# R7FS3A17 register map
Vendor: Renesas; Series: S3; File version: 1.2
CPU: CM4 r0p1, little endian, MPU, FPU, VTOR, 4 interrupt priority bits
Registers are 8-bit, read-write, reset 0x0 unless marked. A register's access mark holds for its fields unless they carry their own. Offsets are from the block's base; [hi:lo] are bit positions.

## DMA — DMAC Module Activation
Base 0x40005200
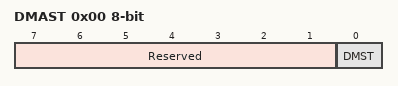
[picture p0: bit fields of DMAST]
0x00 DMAST — DMAC Module Activation Register
  [7:1] Reserved — These bits are read as 0000000. The write value should be 0000000.
  [0] DMST — DMAC Operation Enable
    0=Disabled; 1=Enabled

## DTC — Data Transfer Controller
Base 0x40005400
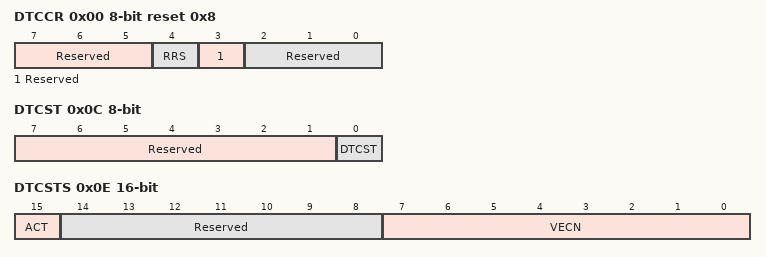
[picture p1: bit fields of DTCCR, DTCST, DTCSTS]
0x00 DTCCR reset 0x8 — DTC Control Register
  [7:5] Reserved — These bits are read as 000. The write value should be 000.
  [4] RRS — DTC Transfer Information Read Skip Enable.
    0=Do not skip transfer information read; 1=Skip transfer information read when vector numbers match
  [3] Reserved — This bit is read as 1. The write value should be 1.
  [2:0] Reserved — These bits are read as 000. The write value should be 000.
0x04 DTCVBR 32-bit — DTC Vector Base Register
  [31:0] DTCVBR — DTC Vector Base Address. Note: A value cannot be set in the lower-order 10 bits. These bits are fixed to 0.
0x0C DTCST — DTC Module Start Register
  [7:1] Reserved — These bits are read as 0000000. The write value should be 0000000.
  [0] DTCST — DTC Module Start
    0=DTC module stop; 1=DTC module start
0x0E DTCSTS 16-bit ro — DTC Status Register
  [15] ACT — DTC Active Flag
    0=DTC transfer operation is not in progress; 1=DTC transfer operation is in progress
  [14:8] Reserved — These bits are read as 0000000.
  [7:0] VECN — DTC-Activating Vector Number Monitoring These bits indicate the vector number for the activating source when DTC transfer is in progress. The value is only valid if DTC transfer is in progress (the value of the ACT flag is 1)

## DBG — Debug Function
Base 0x4001B000
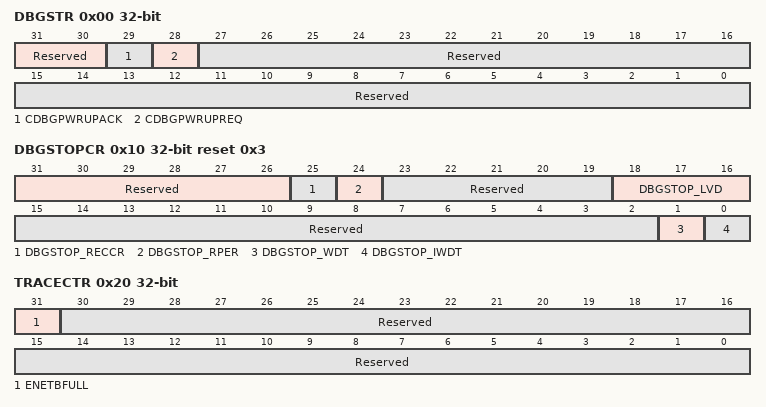
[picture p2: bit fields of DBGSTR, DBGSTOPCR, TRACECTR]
0x00 DBGSTR 32-bit ro — Debug Status Register
  [31:30] Reserved — These bits are read as 00.
  [29] CDBGPWRUPACK — Debug power-up acknowledge
    0=Debug power-up request is not acknowledged; 1=Debug power-up request is acknowledged
  [28] CDBGPWRUPREQ — Debug power-up request
    0=OCD is not requesting debug power-up; 1=OCD is requesting debug power-up
  [27:0] Reserved — These bits are read as 0000000000000000000000000000.
0x10 DBGSTOPCR 32-bit reset 0x3 — Debug Stop Control Register
  [31:26] Reserved — These bits are read as 000000. The write value should be 000000.
  [25] DBGSTOP_RECCR — Mask bit for RAM ECC error reset/interrupt
    0=Enable RAM ECC error reset/interrupt; 1=Mask RAM ECC error reset/interrupt
  [24] DBGSTOP_RPER — Mask bit for RAM parity error reset/interrupt
    0=Enable RAM parity error reset/interrupt; 1=Mask RAM parity error reset/interrupt
  [23:19] Reserved — These bits are read as 00000. The write value should be 00000.
  [18:16] DBGSTOP_LVD — b18: Mask bit for LVD2 reset/interrupt (0:enable / 1:Mask) b17: Mask bit for LVD1 reset/interrupt (0:enable / 1:Mask) b16: Mask bit for LVD0 reset (0:enable / 1:Mask)
  [15:2] Reserved — These bits are read as 00000000000000. The write value should be 00000000000000.
  [1] DBGSTOP_WDT — Mask bit for WDT reset/interrupt
    0=Mask WDT reset/interrupt; 1=Enable WDT reset
  [0] DBGSTOP_IWDT — Mask bit for IWDT reset/interrupt
    0=Mask IWDT reset/interrupt; 1=Enable IWDT reset
0x20 TRACECTR 32-bit — Trace Control Register
  [31] ENETBFULL — Enable bit for halt request by ETB full
    0=ETB full does not cause CPU halt; 1=ETB full cause CPU halt
  [30:0] Reserved — These bits are read as 0000000000000000000000000000000. The write value should be 0000000000000000000000000000000.

## FCACHE — Flash Cache
Base 0x4001C000
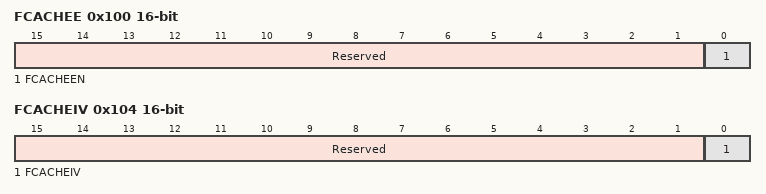
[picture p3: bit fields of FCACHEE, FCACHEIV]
0x100 FCACHEE 16-bit — Flash Cache Enable Register
  [15:1] Reserved — These bits are read as 000000000000000. The write value should be 000000000000000.
  [0] FCACHEEN — FCACHE Enable
    0=FCACHE is disabled; 1=FCACHE is enabled
0x104 FCACHEIV 16-bit — Flash Cache Invalidate Register
  [15:1] Reserved — These bits are read as 000000000000000. The write value should be 000000000000000.
  [0] FCACHEIV write-1-sets read-modifies — FCACHE Invalidation
    0=(Read)not in progress / (Write) no effect; 1=(Read)in progress /(Write) Starting Cache Invalidation
